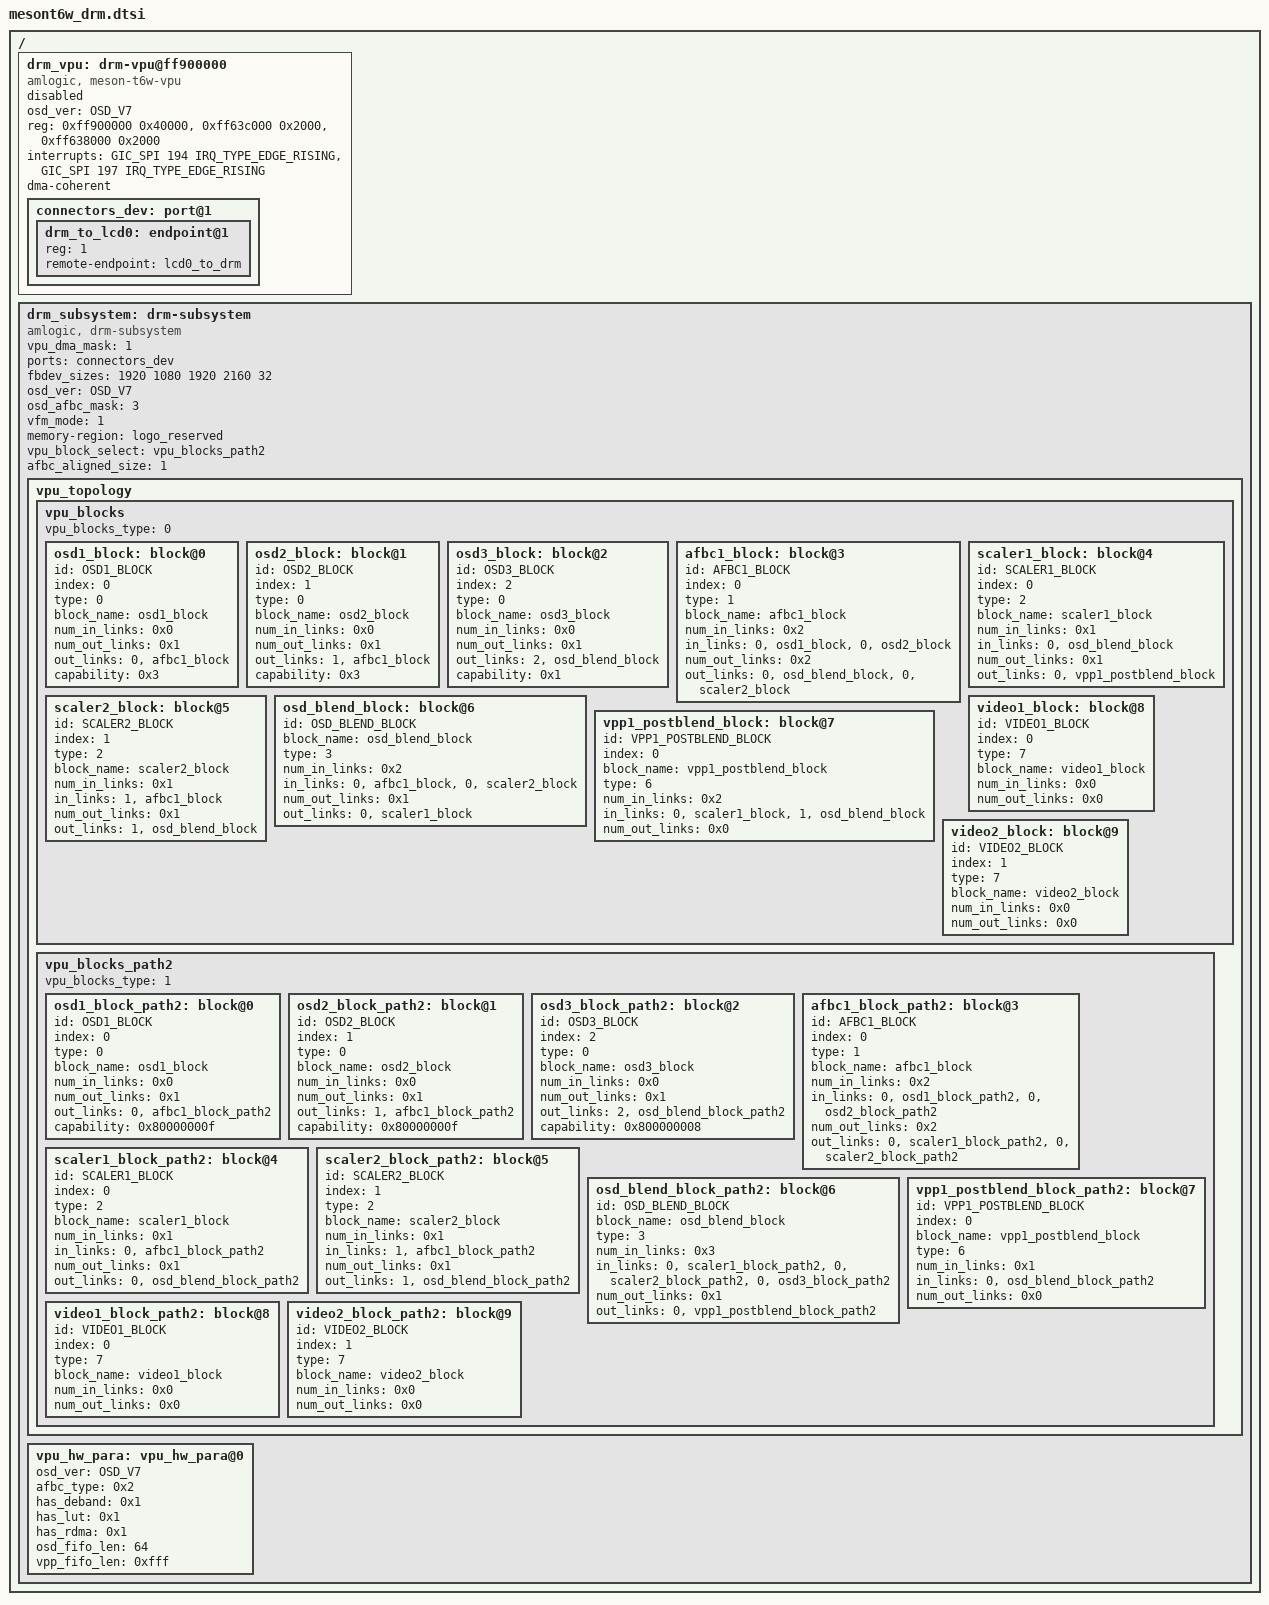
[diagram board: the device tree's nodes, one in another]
// SPDX-License-Identifier: (GPL-2.0+ OR MIT)
/*
 * Copyright (c) 2019 Amlogic, Inc. All rights reserved.
 */
#include <dt-bindings/display/meson-drm-ids.h>
#include "mesont6w.dtsi"

/ {
	drm_vpu: drm-vpu@ff900000  {
		status = "disabled";
		compatible = "amlogic, meson-t6w-vpu";
		osd_ver = /bits/ 8 <OSD_V7>;
		reg = <0xff900000 0x40000>,
			<0xff63c000 0x2000>,
			<0xff638000 0x2000>;
		reg-names = "base", "hhi", "dmc";
		interrupts = <GIC_SPI 194 IRQ_TYPE_EDGE_RISING>,
			<GIC_SPI 197 IRQ_TYPE_EDGE_RISING>;
		interrupt-names = "viu-vsync", "viu2-vsync";

		dma-coherent;
		/*EXTERNAL port for driver outside of drm.*/
		connectors_dev: port@1 {
			#address-cells = <1>;
			#size-cells = <0>;
			drm_to_lcd0: endpoint@1 {
				reg = <1>;
				remote-endpoint = <&lcd0_to_drm>;
			};
		};
	};

	drm_subsystem: drm-subsystem {
		status = "okay";
		compatible = "amlogic, drm-subsystem";
		vpu_dma_mask = <1>; /* 0: <= 4G, 1: > 4G */
		ports = <&connectors_dev>;
		fbdev_sizes = <1920 1080 1920 2160 32>;
		osd_ver = /bits/ 8 <OSD_V7>;
		/* OSD1&OSD2 with afbc, OSD3 has no afbc */
		osd_afbc_mask = <3>;
		vfm_mode = <1>; /** 0:drm mode 1:composer mode */
		memory-region = <&logo_reserved>;
		vpu_block_select = <&vpu_blocks_path2>;
		afbc_aligned_size = <1>; /*0:fbdev alloc non-afbc memory 1:fbdev alloc afbc memory*/

		vpu_topology: vpu_topology {
			vpu_blocks: vpu_blocks {
				/*0:scaler1 after osdblend, 1:scaler1 before osdblend*/
				vpu_blocks_type = <0>;
				osd1_block: block@0 {
					id = /bits/ 8 <OSD1_BLOCK>;
					index = /bits/ 8  <0>;
					type = /bits/ 8  <0>;
					block_name = "osd1_block";
					num_in_links = /bits/ 8  <0x0>;
					num_out_links = /bits/ 8  <0x1>;
					out_links = <0 &afbc1_block>;
					capability = /bits/ 64 <0x3>;
				};
				osd2_block: block@1 {
					id = /bits/ 8  <OSD2_BLOCK>;
					index = /bits/ 8  <1>;
					type = /bits/ 8  <0>;
					block_name = "osd2_block";
					num_in_links = /bits/ 8  <0x0>;
					num_out_links = /bits/ 8  <0x1>;
					out_links = <1 &afbc1_block>;
					capability = /bits/ 64 <0x3>;
				};
				osd3_block: block@2 {
					id = /bits/ 8  <OSD3_BLOCK>;
					index = /bits/ 8  <2>;
					type = /bits/ 8  <0>;
					block_name = "osd3_block";
					num_in_links = /bits/ 8  <0x0>;
					num_out_links = /bits/ 8  <0x1>;
					out_links = <2 &osd_blend_block>;
					capability = /bits/ 64 <0x1>;
				};
				afbc1_block: block@3 {
					id = /bits/ 8  <AFBC1_BLOCK>;
					index = /bits/ 8  <0>;
					type = /bits/ 8  <1>;
					block_name = "afbc1_block";
					num_in_links = /bits/ 8  <0x2>;
					in_links = <0 &osd1_block>,
						   <0 &osd2_block>;
					num_out_links = /bits/ 8  <0x2>;
					out_links = <0 &osd_blend_block>,
						    <0 &scaler2_block>;
				};
				scaler1_block: block@4 {
					id = /bits/ 8  <SCALER1_BLOCK>;
					index = /bits/ 8  <0>;
					type = /bits/ 8  <2>;
					block_name = "scaler1_block";
					num_in_links = /bits/ 8  <0x1>;
					in_links = <0 &osd_blend_block>;
					num_out_links = /bits/ 8  <0x1>;
					out_links = <0 &vpp1_postblend_block>;
				};
				scaler2_block: block@5 {
					id = /bits/ 8  <SCALER2_BLOCK>;
					index = /bits/ 8  <1>;
					type = /bits/ 8  <2>;
					block_name = "scaler2_block";
					num_in_links = /bits/ 8  <0x1>;
					in_links = <1 &afbc1_block>;
					num_out_links = /bits/ 8  <0x1>;
					out_links = <1 &osd_blend_block>;
				};
				osd_blend_block: block@6 {
					id = /bits/ 8  <OSD_BLEND_BLOCK>;
					block_name = "osd_blend_block";
					type = /bits/ 8  <3>;
					num_in_links = /bits/ 8  <0x2>;
					in_links = <0 &afbc1_block>,
						<0 &scaler2_block>;
					num_out_links = /bits/ 8  <0x1>;
					out_links = <0 &scaler1_block>;
				};
				vpp1_postblend_block: block@7 {
					id = /bits/ 8  <VPP1_POSTBLEND_BLOCK>;
					index = /bits/ 8  <0>;
					block_name = "vpp1_postblend_block";
					type = /bits/ 8  <6>;
					num_in_links = /bits/ 8  <0x2>;
					in_links = <0 &scaler1_block>,
						<1 &osd_blend_block>;
					num_out_links = <0x0>;
				};
				video1_block: block@8{
					id = /bits/ 8 <VIDEO1_BLOCK>;
					index = /bits/ 8  <0>;
					type = /bits/ 8  <7>;
					block_name = "video1_block";
					num_in_links = /bits/ 8  <0x0>;
					num_out_links = /bits/ 8  <0x0>;
				};
				video2_block: block@9 {
					id = /bits/ 8 <VIDEO2_BLOCK>;
					index = /bits/ 8  <1>;
					type = /bits/ 8  <7>;
					block_name = "video2_block";
					num_in_links = /bits/ 8  <0x0>;
					num_out_links = /bits/ 8  <0x0>;
				};
			};
			vpu_blocks_path2: vpu_blocks_path2 {
				/*0:scaler1 after osdblend, 1:scaler1 before osdblend*/
				vpu_blocks_type = <1>;
				osd1_block_path2: block@0 {
					id = /bits/ 8 <OSD1_BLOCK>;
					index = /bits/ 8  <0>;
					type = /bits/ 8  <0>;
					block_name = "osd1_block";
					num_in_links = /bits/ 8  <0x0>;
					num_out_links = /bits/ 8  <0x1>;
					out_links = <0 &afbc1_block_path2>;
					capability = /bits/ 64 <0x80000000f>;
				};
				osd2_block_path2: block@1 {
					id = /bits/ 8  <OSD2_BLOCK>;
					index = /bits/ 8  <1>;
					type = /bits/ 8  <0>;
					block_name = "osd2_block";
					num_in_links = /bits/ 8  <0x0>;
					num_out_links = /bits/ 8  <0x1>;
					out_links = <1 &afbc1_block_path2>;
					capability = /bits/ 64 <0x80000000f>;
				};
				osd3_block_path2: block@2 {
					id = /bits/ 8  <OSD3_BLOCK>;
					index = /bits/ 8  <2>;
					type = /bits/ 8  <0>;
					block_name = "osd3_block";
					num_in_links = /bits/ 8  <0x0>;
					num_out_links = /bits/ 8  <0x1>;
					out_links = <2 &osd_blend_block_path2>;
					capability = /bits/ 64 <0x800000008>;
				};
				afbc1_block_path2: block@3 {
					id = /bits/ 8  <AFBC1_BLOCK>;
					index = /bits/ 8  <0>;
					type = /bits/ 8  <1>;
					block_name = "afbc1_block";
					num_in_links = /bits/ 8  <0x2>;
					in_links = <0 &osd1_block_path2>,
						   <0 &osd2_block_path2>;
					num_out_links = /bits/ 8  <0x2>;
					out_links = <0 &scaler1_block_path2>,
						    <0 &scaler2_block_path2>;
				};
				scaler1_block_path2: block@4 {
					id = /bits/ 8  <SCALER1_BLOCK>;
					index = /bits/ 8  <0>;
					type = /bits/ 8  <2>;
					block_name = "scaler1_block";
					num_in_links = /bits/ 8  <0x1>;
					in_links = <0 &afbc1_block_path2>;
					num_out_links = /bits/ 8  <0x1>;
					out_links = <0 &osd_blend_block_path2>;
				};
				scaler2_block_path2: block@5 {
					id = /bits/ 8  <SCALER2_BLOCK>;
					index = /bits/ 8  <1>;
					type = /bits/ 8  <2>;
					block_name = "scaler2_block";
					num_in_links = /bits/ 8  <0x1>;
					in_links = <1 &afbc1_block_path2>;
					num_out_links = /bits/ 8  <0x1>;
					out_links = <1 &osd_blend_block_path2>;
				};
				osd_blend_block_path2: block@6 {
					id = /bits/ 8  <OSD_BLEND_BLOCK>;
					block_name = "osd_blend_block";
					type = /bits/ 8  <3>;
					num_in_links = /bits/ 8  <0x3>;
					in_links = <0 &scaler1_block_path2>,
						<0 &scaler2_block_path2>,
						<0 &osd3_block_path2>;
					num_out_links = /bits/ 8  <0x1>;
					out_links = <0 &vpp1_postblend_block_path2>;
				};
				vpp1_postblend_block_path2: block@7 {
					id = /bits/ 8  <VPP1_POSTBLEND_BLOCK>;
					index = /bits/ 8  <0>;
					block_name = "vpp1_postblend_block";
					type = /bits/ 8  <6>;
					num_in_links = /bits/ 8  <0x1>;
					in_links = <0 &osd_blend_block_path2>;
					num_out_links = <0x0>;
				};
				video1_block_path2: block@8{
					id = /bits/ 8 <VIDEO1_BLOCK>;
					index = /bits/ 8  <0>;
					type = /bits/ 8  <7>;
					block_name = "video1_block";
					num_in_links = /bits/ 8  <0x0>;
					num_out_links = /bits/ 8  <0x0>;
				};
				video2_block_path2: block@9 {
					id = /bits/ 8 <VIDEO2_BLOCK>;
					index = /bits/ 8  <1>;
					type = /bits/ 8  <7>;
					block_name = "video2_block";
					num_in_links = /bits/ 8  <0x0>;
					num_out_links = /bits/ 8  <0x0>;
				};
			};
		};

		vpu_hw_para: vpu_hw_para@0 {
			osd_ver = /bits/ 8 <OSD_V7>;
			afbc_type = /bits/ 8 <0x2>;
			has_deband = /bits/ 8 <0x1>;
			has_lut = /bits/ 8 <0x1>;
			has_rdma = /bits/ 8 <0x1>;
			osd_fifo_len = /bits/ 8 <64>;
			vpp_fifo_len = /bits/ 32 <0xfff>;
		};
	};
};
